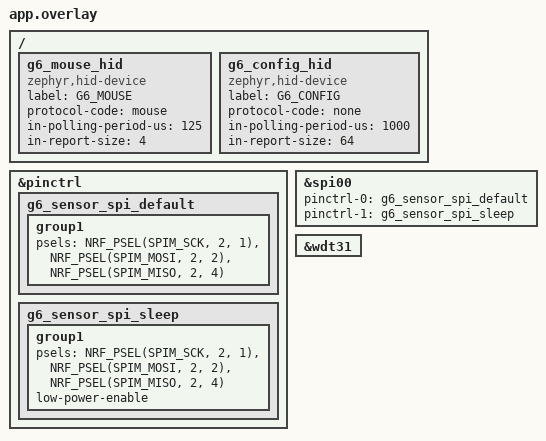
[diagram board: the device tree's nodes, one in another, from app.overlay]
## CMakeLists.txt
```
cmake_minimum_required(VERSION 3.20.0)

find_package(Zephyr REQUIRED HINTS $ENV{ZEPHYR_BASE})
project(g6_he_replacement)

target_include_directories(app PRIVATE include)

target_sources(app PRIVATE
  src/g6_config.c
  src/g6_input_guard.c
  src/g6_hw_nrf54.c
  src/g6_usb.c
  src/main.c
)
```

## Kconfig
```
mainmenu "G6 HE replacement firmware"

source "Kconfig.zephyr"
```

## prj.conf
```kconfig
CONFIG_USB_DEVICE_STACK_NEXT=y
CONFIG_USBD_HID_SUPPORT=y
CONFIG_USBD_HID_SET_POLLING_PERIOD=y
CONFIG_HWINFO=y

CONFIG_GPIO=y
CONFIG_SPI=y
CONFIG_WATCHDOG=y

CONFIG_LOG=n
CONFIG_CONSOLE=n
CONFIG_SERIAL=n
CONFIG_UART_CONSOLE=n

CONFIG_MAIN_STACK_SIZE=4096
CONFIG_SYSTEM_WORKQUEUE_STACK_SIZE=2048
CONFIG_ASSERT=y

CONFIG_BUILD_OUTPUT_BIN=y
CONFIG_BUILD_OUTPUT_HEX=y
```

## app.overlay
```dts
#include <zephyr/dt-bindings/gpio/gpio.h>
#include <zephyr/dt-bindings/pinctrl/nrf-pinctrl.h>

&pinctrl {
	g6_sensor_spi_default: g6_sensor_spi_default {
		group1 {
			psels = <NRF_PSEL(SPIM_SCK, 2, 1)>,
				<NRF_PSEL(SPIM_MOSI, 2, 2)>,
				<NRF_PSEL(SPIM_MISO, 2, 4)>;
		};
	};

	g6_sensor_spi_sleep: g6_sensor_spi_sleep {
		group1 {
			psels = <NRF_PSEL(SPIM_SCK, 2, 1)>,
				<NRF_PSEL(SPIM_MOSI, 2, 2)>,
				<NRF_PSEL(SPIM_MISO, 2, 4)>;
			low-power-enable;
		};
	};
};

&spi00 {
	status = "okay";
	pinctrl-0 = <&g6_sensor_spi_default>;
	pinctrl-1 = <&g6_sensor_spi_sleep>;
	pinctrl-names = "default", "sleep";
};

/ {
	g6_mouse_hid: g6_mouse_hid {
		compatible = "zephyr,hid-device";
		label = "G6_MOUSE";
		protocol-code = "mouse";
		in-polling-period-us = <125>;
		in-report-size = <4>;
	};

	g6_config_hid: g6_config_hid {
		compatible = "zephyr,hid-device";
		label = "G6_CONFIG";
		protocol-code = "none";
		in-polling-period-us = <1000>;
		in-report-size = <64>;
	};
};

&wdt31 {
	status = "okay";
};
```

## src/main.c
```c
#include <errno.h>
#include <string.h>

#include <zephyr/device.h>
#include <zephyr/drivers/watchdog.h>
#include <zephyr/kernel.h>
#include <zephyr/sys/atomic.h>
#include <zephyr/sys/util.h>
#include <zephyr/usb/class/hid.h>
#include <zephyr/usb/class/usbd_hid.h>
#include <zephyr/usb/usbd.h>

#include "g6_config.h"
#include "g6_hw.h"
#include "g6_input_guard.h"
#include "g6_usb.h"

#define G6_MOUSE_REPORT_SIZE 4U
#define G6_INPUT_LOOP_US 50U
#define G6_WATCHDOG_TIMEOUT_MS 1500U
#define G6_USB_RESTART_DELAY_MS 250U

static const uint8_t mouse_report_desc[] = HID_MOUSE_REPORT_DESC(8);

static const uint8_t config_report_desc[] = {
	HID_USAGE_PAGE16(0xFF00),
	HID_USAGE(0x01),
	HID_COLLECTION(HID_COLLECTION_APPLICATION),
		HID_REPORT_ID(G6_FEATURE_REPORT_ID),
		HID_LOGICAL_MIN8(0),
		HID_LOGICAL_MAX16(0xFF, 0x00),
		HID_REPORT_SIZE(8),
		HID_REPORT_COUNT(G6_FEATURE_FRAME_SIZE),
		HID_FEATURE(0x02),
	HID_END_COLLECTION,
};

static const struct device *const mouse_dev =
	DEVICE_DT_GET(DT_NODELABEL(g6_mouse_hid));
static const struct device *const config_dev =
	DEVICE_DT_GET(DT_NODELABEL(g6_config_hid));
static const struct device *const watchdog_dev =
	DEVICE_DT_GET(DT_ALIAS(watchdog0));

static struct g6_config active_config;
static struct g6_health health;
static struct g6_input_guard input_guard;
static uint8_t feature_response[G6_FEATURE_FRAME_SIZE];
static struct k_mutex state_lock;
static atomic_t mouse_ready;
static atomic_t config_ready;
static int watchdog_channel = -1;
static struct usbd_context *usb_context;
static struct k_work_delayable usb_restart_work;
static uint32_t pending_polling_period_us;

static void record_error(int ret)
{
	if (ret >= 0) {
		return;
	}
	k_mutex_lock(&state_lock, K_FOREVER);
	health.last_error = (uint32_t)-ret;
	k_mutex_unlock(&state_lock);
}

static void usb_restart_handler(struct k_work *work)
{
	uint32_t period_us = pending_polling_period_us;
	int ret;

	ARG_UNUSED(work);
	atomic_clear(&mouse_ready);
	atomic_clear(&config_ready);

	ret = usbd_disable(usb_context);
	if (ret != 0) {
		record_error(ret);
		return;
	}
	ret = usbd_shutdown(usb_context);
	if (ret != 0) {
		record_error(ret);
		return;
	}
	ret = hid_device_set_in_polling(mouse_dev, period_us);
	if (ret != 0) {
		record_error(ret);
		return;
	}
	ret = usbd_init(usb_context);
	if (ret != 0) {
		record_error(ret);
		return;
	}
	ret = usbd_enable(usb_context);
	record_error(ret);
}

static void update_health_locked(void)
{
	health.uptime_ms = k_uptime_get_32();
	health.sensor_ready = g6_hw_sensor_ready();
	health.buttons_ready = g6_hw_buttons_ready();
	health.usb_ready = atomic_get(&mouse_ready) &&
			   atomic_get(&config_ready);
	health.recovery_available = 0U;
}

static void apply_active_config_locked(uint16_t old_polling)
{
	int ret = g6_hw_apply_config(&active_config);

	if (ret != 0) {
		health.last_error = (uint32_t)-ret;
	}
	if (active_config.polling_hz != old_polling) {
		pending_polling_period_us =
			g6_polling_period_us(active_config.polling_hz);
		k_work_reschedule(&usb_restart_work,
				  K_MSEC(G6_USB_RESTART_DELAY_MS));
	}
}

static void process_control_event_locked(enum g6_control_event event)
{
	uint16_t old_polling = active_config.polling_hz;

	if (event == G6_CONTROL_CYCLE_POLLING) {
		g6_cycle_polling(&active_config);
	} else if (event == G6_CONTROL_CYCLE_DPI) {
		g6_cycle_dpi(&active_config);
	} else {
		return;
	}

	/* A mode/config shortcut must not leave a host-side pressed button. */
	g6_input_guard_reset(&input_guard);
	health.control_events++;
	apply_active_config_locked(old_polling);
}

static void iface_ready(const struct device *dev, bool ready)
{
	if (dev == mouse_dev) {
		atomic_set(&mouse_ready, ready);
	} else if (dev == config_dev) {
		atomic_set(&config_ready, ready);
	}
}

static int config_get_report(const struct device *dev, uint8_t type,
			     uint8_t id, uint16_t len, uint8_t *buf)
{
	uint16_t copy_len;

	ARG_UNUSED(dev);
	if (type != HID_REPORT_TYPE_FEATURE ||
	    id != G6_FEATURE_REPORT_ID || buf == NULL) {
		return -ENOTSUP;
	}

	copy_len = MIN(len, (uint16_t)G6_FEATURE_FRAME_SIZE);
	k_mutex_lock(&state_lock, K_FOREVER);
	memcpy(buf, feature_response, copy_len);
	k_mutex_unlock(&state_lock);
	return copy_len;
}

static int config_set_report(const struct device *dev, uint8_t type,
			     uint8_t id, uint16_t len, const uint8_t *buf)
{
	const uint8_t *frame = buf;
	enum g6_status status;
	uint16_t old_polling;

	ARG_UNUSED(dev);
	if (type != HID_REPORT_TYPE_FEATURE ||
	    id != G6_FEATURE_REPORT_ID || buf == NULL) {
		return -ENOTSUP;
	}

	if (len == G6_FEATURE_FRAME_SIZE + 1U &&
	    buf[0] == G6_FEATURE_REPORT_ID) {
		frame = &buf[1];
		len--;
	}
	if (len != G6_FEATURE_FRAME_SIZE) {
		return -EMSGSIZE;
	}

	k_mutex_lock(&state_lock, K_FOREVER);
	old_polling = active_config.polling_hz;
	update_health_locked();
	status = g6_process_command(&active_config, &health, frame,
				    feature_response);
	if (status == G6_STATUS_OK) {
		g6_input_guard_reset(&input_guard);
		apply_active_config_locked(old_polling);
	}
	k_mutex_unlock(&state_lock);
	return 0;
}

static struct hid_device_ops mouse_ops = {
	.iface_ready = iface_ready,
};

static struct hid_device_ops config_ops = {
	.iface_ready = iface_ready,
	.get_report = config_get_report,
	.set_report = config_set_report,
};

static int watchdog_start(void)
{
	struct wdt_timeout_cfg timeout = {
		.window = {
			.min = 0U,
			.max = G6_WATCHDOG_TIMEOUT_MS,
		},
		.callback = NULL,
		.flags = WDT_FLAG_RESET_SOC,
	};
	int ret;

	if (!device_is_ready(watchdog_dev)) {
		return -ENODEV;
	}
	watchdog_channel = wdt_install_timeout(watchdog_dev, &timeout);
	if (watchdog_channel < 0) {
		return watchdog_channel;
	}
	ret = wdt_setup(watchdog_dev, WDT_OPT_PAUSE_HALTED_BY_DBG);
	return ret;
}

static void watchdog_feed_if_healthy(void)
{
	int ret;

	if (watchdog_channel < 0) {
		return;
	}
	ret = wdt_feed(watchdog_dev, watchdog_channel);
	k_mutex_lock(&state_lock, K_FOREVER);
	if (ret == 0) {
		health.watchdog_feeds++;
	} else {
		health.last_error = (uint32_t)-ret;
	}
	k_mutex_unlock(&state_lock);
}

static int initialize(void)
{
	struct usbd_context *usb;
	int ret;

	k_mutex_init(&state_lock);
	k_work_init_delayable(&usb_restart_work, usb_restart_handler);
	g6_config_defaults(&active_config);
	g6_input_guard_reset(&input_guard);
	g6_frame_init(feature_response, 0U, G6_CMD_GET_CONFIG);
	feature_response[7] = G6_STATUS_NOT_READY;
	g6_frame_finalize(feature_response);

	ret = g6_hw_init();
	if (ret != 0) {
		return ret;
	}

	if (!device_is_ready(mouse_dev) || !device_is_ready(config_dev)) {
		return -ENODEV;
	}
	ret = hid_device_register(mouse_dev, mouse_report_desc,
				  sizeof(mouse_report_desc), &mouse_ops);
	if (ret != 0) {
		return ret;
	}
	ret = hid_device_register(config_dev, config_report_desc,
				  sizeof(config_report_desc), &config_ops);
	if (ret != 0) {
		return ret;
	}
	ret = hid_device_set_in_polling(
		mouse_dev, g6_polling_period_us(active_config.polling_hz));
	if (ret != 0) {
		return ret;
	}

	usb = g6_usb_init();
	if (usb == NULL) {
		return -ENODEV;
	}
	usb_context = usb;
	ret = usbd_enable(usb);
	if (ret != 0) {
		return ret;
	}

	ret = watchdog_start();
	return ret == -ENODEV ? 0 : ret;
}

int main(void)
{
	uint8_t report[G6_MOUSE_REPORT_SIZE] __aligned(4);
	uint32_t last_watchdog_feed = 0U;
	int ret = initialize();

	if (ret != 0) {
		k_panic();
	}

	while (true) {
		struct g6_input_sample sample;
		enum g6_control_event control_event = G6_CONTROL_NONE;
		uint8_t filtered_buttons = 0U;
		bool guard_changed = false;
		uint32_t now;

		ret = g6_hw_poll(&sample);
		k_mutex_lock(&state_lock, K_FOREVER);
		health.input_loops++;
		if (ret != 0) {
			health.last_error = (uint32_t)-ret;
		}
		k_mutex_unlock(&state_lock);

		now = k_uptime_get_32();
		if (ret == 0) {
			guard_changed = g6_input_guard_process(
				&input_guard, now, sample.raw_buttons,
				&filtered_buttons, &control_event);
			if (control_event != G6_CONTROL_NONE) {
				k_mutex_lock(&state_lock, K_FOREVER);
				process_control_event_locked(control_event);
				health.suppressed_chord_reports++;
				k_mutex_unlock(&state_lock);
			}
		}

		if (ret == 0 && (sample.changed || guard_changed) &&
		    atomic_get(&mouse_ready)) {
			k_mutex_lock(&state_lock, K_FOREVER);
			report[0] = g6_apply_button_map(
				&active_config, filtered_buttons);
			k_mutex_unlock(&state_lock);
			report[1] = (uint8_t)CLAMP(sample.dx, -127, 127);
			report[2] = (uint8_t)CLAMP(sample.dy, -127, 127);
			report[3] = (uint8_t)sample.wheel;

			ret = hid_device_submit_report(
				mouse_dev, sizeof(report), report);
			k_mutex_lock(&state_lock, K_FOREVER);
			if (ret == 0) {
				health.usb_reports++;
			} else {
				health.usb_errors++;
				health.last_error = (uint32_t)-ret;
			}
			k_mutex_unlock(&state_lock);
		}

		if ((now - last_watchdog_feed) >=
		    (G6_WATCHDOG_TIMEOUT_MS / 3U)) {
			watchdog_feed_if_healthy();
			last_watchdog_feed = now;
		}

		k_busy_wait(G6_INPUT_LOOP_US);
	}
}
```

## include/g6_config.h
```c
#ifndef G6_CONFIG_H
#define G6_CONFIG_H

#include <stdbool.h>
#include <stddef.h>
#include <stdint.h>

#define G6_PROTOCOL_VERSION 1U
#define G6_FIRMWARE_VERSION "0.2.0-dvt1"
#define G6_FEATURE_REPORT_ID 0x51U
#define G6_FEATURE_FRAME_SIZE 63U
#define G6_FEATURE_PAYLOAD_SIZE 50U

#define G6_DPI_MIN 1U
#define G6_DPI_MAX 40000U
#define G6_SENSOR_FPS_MIN 20000U
#define G6_SENSOR_FPS_MAX 20000U
#define G6_BUTTON_COUNT 8U

enum g6_command {
	G6_CMD_GET_CAPABILITIES = 0x01,
	G6_CMD_GET_CONFIG = 0x02,
	G6_CMD_SET_DPI = 0x10,
	G6_CMD_SET_POLLING = 0x11,
	G6_CMD_SET_SENSOR_FPS = 0x12,
	G6_CMD_SET_BUTTON_MAP = 0x13,
	G6_CMD_SET_SWITCH_MODE = 0x14,
	G6_CMD_SAVE = 0x20,
	G6_CMD_FACTORY_RESET = 0x21,
	G6_CMD_GET_HEALTH = 0x30,
	G6_CMD_REBOOT_RECOVERY = 0x31,
};

enum g6_status {
	G6_STATUS_OK = 0,
	G6_STATUS_BAD_MAGIC = 1,
	G6_STATUS_BAD_VERSION = 2,
	G6_STATUS_BAD_LENGTH = 3,
	G6_STATUS_BAD_CRC = 4,
	G6_STATUS_BAD_COMMAND = 5,
	G6_STATUS_BAD_VALUE = 6,
	G6_STATUS_NOT_READY = 7,
	G6_STATUS_NOT_IMPLEMENTED = 8,
};

enum g6_switch_mode {
	G6_SWITCH_OPTICAL = 0,
	G6_SWITCH_MAGNETIC = 1,
	G6_SWITCH_HYBRID = 2,
};

enum g6_button_action {
	G6_ACTION_NONE = 0,
	G6_ACTION_LEFT = 1,
	G6_ACTION_RIGHT = 2,
	G6_ACTION_MIDDLE = 3,
	G6_ACTION_BACK = 4,
	G6_ACTION_FORWARD = 5,
	G6_ACTION_DPI_UP = 6,
	G6_ACTION_DPI_DOWN = 7,
};

struct g6_config {
	uint16_t dpi;
	uint16_t polling_hz;
	uint16_t sensor_fps;
	uint8_t switch_mode;
	uint8_t button_map[G6_BUTTON_COUNT];
};

struct g6_health {
	uint32_t uptime_ms;
	uint32_t input_loops;
	uint32_t usb_reports;
	uint32_t usb_errors;
	uint32_t watchdog_feeds;
	uint32_t last_error;
	uint8_t sensor_ready;
	uint8_t buttons_ready;
	uint8_t usb_ready;
	uint8_t recovery_available;
	uint32_t control_events;
	uint32_t suppressed_chord_reports;
};

void g6_config_defaults(struct g6_config *cfg);
bool g6_config_valid(const struct g6_config *cfg);
bool g6_polling_hz_valid(uint16_t polling_hz);
uint32_t g6_polling_period_us(uint16_t polling_hz);
void g6_cycle_dpi(struct g6_config *cfg);
void g6_cycle_polling(struct g6_config *cfg);
uint8_t g6_apply_button_map(const struct g6_config *cfg, uint8_t raw_buttons);

uint32_t g6_crc32(const uint8_t *data, size_t len);
void g6_frame_init(uint8_t frame[G6_FEATURE_FRAME_SIZE],
		   uint8_t sequence, uint8_t command);
void g6_frame_finalize(uint8_t frame[G6_FEATURE_FRAME_SIZE]);
enum g6_status g6_frame_validate(
	const uint8_t frame[G6_FEATURE_FRAME_SIZE]);

enum g6_status g6_process_command(
	struct g6_config *cfg,
	const struct g6_health *health,
	const uint8_t request[G6_FEATURE_FRAME_SIZE],
	uint8_t response[G6_FEATURE_FRAME_SIZE]);

#endif
```

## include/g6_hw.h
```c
#ifndef G6_HW_H
#define G6_HW_H

#include <stdbool.h>
#include <stdint.h>

#include "g6_config.h"

struct g6_input_sample {
	int16_t dx;
	int16_t dy;
	int8_t wheel;
	uint8_t raw_buttons;
	bool changed;
};

int g6_hw_init(void);
int g6_hw_apply_config(const struct g6_config *cfg);
int g6_hw_poll(struct g6_input_sample *sample);
bool g6_hw_sensor_ready(void);
bool g6_hw_buttons_ready(void);

#endif
```

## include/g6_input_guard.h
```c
#ifndef G6_INPUT_GUARD_H
#define G6_INPUT_GUARD_H

#include <stdbool.h>
#include <stdint.h>

/* Raw board button bit positions: left, right, middle, back, forward. */
#define G6_RAW_BUTTON_MIDDLE (1U << 2)
#define G6_RAW_BUTTON_BACK (1U << 3)
#define G6_RAW_BUTTON_FORWARD (1U << 4)

enum g6_control_event {
	G6_CONTROL_NONE = 0,
	G6_CONTROL_CYCLE_POLLING,
	G6_CONTROL_CYCLE_DPI,
};

/*
 * The production DVT reports ghost side-button input while the physical
 * middle+side shortcuts are used. This guard delays publication of chord
 * members briefly, consumes a recognised shortcut, and always emits a
 * neutral release when a consumed chord ends.
 */
struct g6_input_guard {
	uint8_t reported_buttons;
	uint32_t chord_deadline_ms;
	bool chord_window_active;
	bool combo_active;
};

void g6_input_guard_reset(struct g6_input_guard *guard);
bool g6_input_guard_process(struct g6_input_guard *guard, uint32_t now_ms,
			    uint8_t raw_buttons, uint8_t *filtered_buttons,
			    enum g6_control_event *event);

#endif
```

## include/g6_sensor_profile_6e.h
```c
#ifndef G6_SENSOR_PROFILE_6E_H
#define G6_SENSOR_PROFILE_6E_H

#include <stdint.h>

/* 268 register/value pairs from production image address 0x2004f725. */
static const uint8_t g6_sensor_6e_init_pairs[] = {
	0x7f, 0x07, 0x40, 0x41, 0x41, 0x0f, 0x42, 0x28,
	0x43, 0x00, 0x4a, 0x08, 0x51, 0x16, 0x53, 0x04,
	0x7f, 0x0e, 0x55, 0xfc, 0x56, 0xff, 0x7f, 0x01,
	0x43, 0xf8, 0x55, 0x28, 0x57, 0x1a, 0x5a, 0x20,
	0x5b, 0x0c, 0x7f, 0x05, 0x43, 0x64, 0x44, 0x04,
	0x46, 0x1b, 0x49, 0xff, 0x55, 0xfc, 0x5e, 0xc3,
	0x5f, 0x80, 0x61, 0x31, 0x6d, 0xea, 0x6e, 0xcf,
	0x4a, 0x15, 0x60, 0x13, 0x7b, 0x48, 0x7f, 0x06,
	0x70, 0x14, 0x71, 0xe0, 0x6b, 0x20, 0x6d, 0x78,
	0x6e, 0x60, 0x44, 0x23, 0x46, 0xb9, 0x53, 0x01,
	0x61, 0x00, 0x63, 0x00, 0x7f, 0x08, 0x63, 0x08,
	0x6b, 0x40, 0x6d, 0x68, 0x73, 0x18, 0x75, 0x2c,
	0x79, 0xc8, 0x7a, 0x0d, 0x7c, 0x2a, 0x7f, 0x09,
	0x53, 0x4a, 0x60, 0x1f, 0x61, 0x1f, 0x62, 0x01,
	0x63, 0x01, 0x64, 0x1f, 0x65, 0x1f, 0x66, 0x01,
	0x67, 0x01, 0x68, 0x01, 0x69, 0x01, 0x6a, 0x1f,
	0x6b, 0x1f, 0x6c, 0x01, 0x6d, 0x01, 0x6e, 0x1f,
	0x6f, 0x1f, 0x40, 0x03, 0x41, 0x00, 0x42, 0x04,
	0x43, 0x28, 0x44, 0x88, 0x45, 0x11, 0x47, 0x03,
	0x4f, 0x0c, 0x51, 0x08, 0x73, 0x0a, 0x7f, 0x0a,
	0x44, 0x43, 0x48, 0x80, 0x50, 0x25, 0x51, 0x8f,
	0x52, 0x40, 0x53, 0x1f, 0x56, 0x90, 0x57, 0x01,
	0x4f, 0xd0, 0x59, 0x3f, 0x7f, 0x0c, 0x41, 0x10,
	0x43, 0x38, 0x44, 0x02, 0x45, 0x02, 0x4e, 0x0a,
	0x47, 0x02, 0x48, 0x01, 0x49, 0x04, 0x55, 0x02,
	0x5c, 0x9e, 0x42, 0x00, 0x4a, 0x20, 0x4b, 0x1f,
	0x4c, 0x68, 0x4d, 0x90, 0x53, 0x1e, 0x54, 0x1a,
	0x50, 0x14, 0x51, 0x15, 0x61, 0x18, 0x62, 0x08,
	0x7f, 0x0d, 0x50, 0x66, 0x52, 0x09, 0x51, 0x00,
	0x5a, 0x47, 0x5b, 0x66, 0x5c, 0xf4, 0x5d, 0x6c,
	0x71, 0x28, 0x70, 0x00, 0x73, 0x29, 0x72, 0x00,
	0x75, 0x28, 0x74, 0x00, 0x77, 0x29, 0x76, 0x00,
	0x7f, 0x10, 0x42, 0x1c, 0x43, 0xd0, 0x45, 0x11,
	0x46, 0x20, 0x48, 0x0a, 0x49, 0x0f, 0x4b, 0x09,
	0x4c, 0xc4, 0x7f, 0x14, 0x43, 0x73, 0x52, 0x19,
	0x62, 0x04, 0x63, 0x04, 0x65, 0x81, 0x53, 0x50,
	0x54, 0xd8, 0x7f, 0x15, 0x41, 0xa2, 0x4c, 0x04,
	0x56, 0x28, 0x6f, 0x28, 0x70, 0x04, 0x71, 0x04,
	0x77, 0x02, 0x7d, 0x10, 0x45, 0xf4, 0x47, 0x44,
	0x4b, 0x12, 0x7f, 0x16, 0x57, 0x43, 0x58, 0x43,
	0x59, 0x43, 0x5a, 0x43, 0x5d, 0x32, 0x5e, 0x32,
	0x69, 0x1e, 0x6a, 0x22, 0x6b, 0x22, 0x6c, 0x22,
	0x6d, 0x22, 0x6e, 0x18, 0x6f, 0x18, 0x70, 0x18,
	0x71, 0x18, 0x73, 0x00, 0x74, 0xda, 0x75, 0xbe,
	0x78, 0x0e, 0x7f, 0x18, 0x41, 0x02, 0x43, 0x80,
	0x44, 0x1f, 0x45, 0x01, 0x46, 0x82, 0x48, 0x65,
	0x49, 0x12, 0x4a, 0x0f, 0x4b, 0x00, 0x4c, 0x28,
	0x4d, 0x38, 0x4e, 0x32, 0x4f, 0x71, 0x50, 0x34,
	0x51, 0x54, 0x52, 0x38, 0x53, 0x5f, 0x54, 0x90,
	0x55, 0x7f, 0x59, 0xa6, 0x5a, 0x30, 0x5b, 0x2c,
	0x5c, 0x60, 0x5d, 0x06, 0x5e, 0x01, 0x5f, 0x48,
	0x60, 0x44, 0x61, 0x14, 0x62, 0x2c, 0x63, 0x48,
	0x64, 0x40, 0x65, 0x75, 0x67, 0x4c, 0x69, 0x85,
	0x6b, 0x60, 0x6d, 0xf5, 0x6e, 0x06, 0x6f, 0x06,
	0x70, 0x22, 0x71, 0xf2, 0x72, 0xf6, 0x76, 0x00,
	0x77, 0x32, 0x78, 0x88, 0x79, 0x99, 0x7a, 0x00,
	0x7e, 0xb0, 0x7f, 0x19, 0x40, 0x43, 0x41, 0x32,
	0x44, 0x32, 0x46, 0xe6, 0x4b, 0x01, 0x4c, 0x01,
	0x52, 0x15, 0x53, 0x12, 0x54, 0x23, 0x56, 0x70,
	0x57, 0x22, 0x58, 0x13, 0x5f, 0x7f, 0x6e, 0x8f,
	0x7f, 0x00, 0x5b, 0x40, 0x45, 0x3f, 0x44, 0x1f,
	0x63, 0x3f, 0x62, 0x1f, 0x48, 0xa6, 0x49, 0x13,
	0x4a, 0x83, 0x4b, 0x13, 0x4f, 0xfc, 0x4e, 0x4e,
	0x52, 0x70, 0x51, 0x4e, 0x5a, 0x80, 0x47, 0x01,
	0x57, 0x20, 0x64, 0x08, 0x65, 0x07, 0x66, 0x13,
	0x77, 0x9e, 0x7d, 0x09, 0x7f, 0x07, 0x40, 0x40,
	0x7f, 0x00, 0x40, 0x80, 0x55, 0x02, 0x22, 0x01,
};

/* Four register/value pairs from production image address 0x2004f71d. */
static const uint8_t g6_sensor_6e_post_pairs[] = {
	0x22, 0x00, 0x55, 0x00, 0x40, 0x00, 0x68, 0x01,
};

#endif
```

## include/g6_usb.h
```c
#ifndef G6_USB_H
#define G6_USB_H

#include <zephyr/usb/usbd.h>

struct usbd_context *g6_usb_init(void);

#endif
```

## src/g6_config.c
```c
#include "g6_config.h"

#include <string.h>

#define G6_FRAME_MAGIC_0 'G'
#define G6_FRAME_MAGIC_1 '6'
#define G6_FRAME_MAGIC_2 'H'
#define G6_FRAME_MAGIC_3 '1'

#define G6_FRAME_VERSION_OFFSET 4U
#define G6_FRAME_SEQUENCE_OFFSET 5U
#define G6_FRAME_COMMAND_OFFSET 6U
#define G6_FRAME_STATUS_OFFSET 7U
#define G6_FRAME_LENGTH_OFFSET 8U
#define G6_FRAME_PAYLOAD_OFFSET 9U
#define G6_FRAME_CRC_OFFSET 59U

#define G6_CAP_WIRED_USB (1U << 0)
#define G6_CAP_HIGH_SPEED_USB (1U << 1)
#define G6_CAP_DYNAMIC_POLLING (1U << 2)
#define G6_CAP_BUTTON_REMAP (1U << 3)
#define G6_CAP_WATCHDOG (1U << 4)
#define G6_CAP_SENSOR_PROFILE_6E (1U << 5)
#define G6_CAP_OPTICAL_SWITCHES (1U << 6)

static uint16_t get_le16(const uint8_t *src)
{
	return (uint16_t)src[0] | ((uint16_t)src[1] << 8);
}

static uint32_t get_le32(const uint8_t *src)
{
	return (uint32_t)src[0] |
	       ((uint32_t)src[1] << 8) |
	       ((uint32_t)src[2] << 16) |
	       ((uint32_t)src[3] << 24);
}

static void put_le16(uint8_t *dst, uint16_t value)
{
	dst[0] = (uint8_t)value;
	dst[1] = (uint8_t)(value >> 8);
}

static void put_le32(uint8_t *dst, uint32_t value)
{
	dst[0] = (uint8_t)value;
	dst[1] = (uint8_t)(value >> 8);
	dst[2] = (uint8_t)(value >> 16);
	dst[3] = (uint8_t)(value >> 24);
}

void g6_config_defaults(struct g6_config *cfg)
{
	static const uint8_t default_map[G6_BUTTON_COUNT] = {
		G6_ACTION_LEFT,
		G6_ACTION_RIGHT,
		G6_ACTION_MIDDLE,
		G6_ACTION_BACK,
		G6_ACTION_FORWARD,
		G6_ACTION_DPI_UP,
		G6_ACTION_DPI_DOWN,
		G6_ACTION_NONE,
	};

	cfg->dpi = 1600U;
	cfg->polling_hz = 1000U;
	cfg->sensor_fps = 20000U;
	cfg->switch_mode = G6_SWITCH_OPTICAL;
	memcpy(cfg->button_map, default_map, sizeof(default_map));
}

bool g6_polling_hz_valid(uint16_t polling_hz)
{
	switch (polling_hz) {
	case 125U:
	case 500U:
	case 1000U:
	case 2000U:
	case 4000U:
	case 8000U:
		return true;
	default:
		return false;
	}
}

uint32_t g6_polling_period_us(uint16_t polling_hz)
{
	return g6_polling_hz_valid(polling_hz) ?
		       (1000000U / polling_hz) : 0U;
}

void g6_cycle_dpi(struct g6_config *cfg)
{
	static const uint16_t stages[] = {400U, 800U, 1600U, 3200U, 5000U};
	size_t i;

	if (cfg == NULL) {
		return;
	}
	for (i = 0U; i < sizeof(stages) / sizeof(stages[0]); ++i) {
		if (cfg->dpi == stages[i]) {
			cfg->dpi = stages[(i + 1U) %
					(sizeof(stages) / sizeof(stages[0]))];
			return;
		}
	}
	cfg->dpi = stages[0];
}

void g6_cycle_polling(struct g6_config *cfg)
{
	static const uint16_t stages[] = {125U, 500U, 1000U, 2000U, 4000U, 8000U};
	size_t i;

	if (cfg == NULL) {
		return;
	}
	for (i = 0U; i < sizeof(stages) / sizeof(stages[0]); ++i) {
		if (cfg->polling_hz == stages[i]) {
			cfg->polling_hz = stages[(i + 1U) %
					(sizeof(stages) / sizeof(stages[0]))];
			return;
		}
	}
	cfg->polling_hz = stages[0];
}

bool g6_config_valid(const struct g6_config *cfg)
{
	size_t i;

	if (cfg == NULL ||
	    cfg->dpi < G6_DPI_MIN || cfg->dpi > G6_DPI_MAX ||
	    !g6_polling_hz_valid(cfg->polling_hz) ||
	    cfg->sensor_fps < G6_SENSOR_FPS_MIN ||
	    cfg->sensor_fps > G6_SENSOR_FPS_MAX ||
	    cfg->switch_mode > G6_SWITCH_HYBRID) {
		return false;
	}

	for (i = 0U; i < G6_BUTTON_COUNT; ++i) {
		if (cfg->button_map[i] > G6_ACTION_DPI_DOWN) {
			return false;
		}
	}

	return true;
}

uint8_t g6_apply_button_map(const struct g6_config *cfg, uint8_t raw_buttons)
{
	uint8_t mapped = 0U;
	size_t i;

	for (i = 0U; i < G6_BUTTON_COUNT; ++i) {
		uint8_t action;

		if ((raw_buttons & (1U << i)) == 0U) {
			continue;
		}

		action = cfg->button_map[i];
		if (action >= G6_ACTION_LEFT && action <= G6_ACTION_FORWARD) {
			mapped |= 1U << (action - G6_ACTION_LEFT);
		}
	}

	return mapped;
}

uint32_t g6_crc32(const uint8_t *data, size_t len)
{
	uint32_t crc = 0xFFFFFFFFU;
	size_t i;

	for (i = 0U; i < len; ++i) {
		uint32_t byte = data[i];
		unsigned int bit;

		crc ^= byte;
		for (bit = 0U; bit < 8U; ++bit) {
			uint32_t mask = 0U - (crc & 1U);
			crc = (crc >> 1) ^ (0xEDB88320U & mask);
		}
	}

	return ~crc;
}

void g6_frame_init(uint8_t frame[G6_FEATURE_FRAME_SIZE],
		   uint8_t sequence, uint8_t command)
{
	memset(frame, 0, G6_FEATURE_FRAME_SIZE);
	frame[0] = G6_FRAME_MAGIC_0;
	frame[1] = G6_FRAME_MAGIC_1;
	frame[2] = G6_FRAME_MAGIC_2;
	frame[3] = G6_FRAME_MAGIC_3;
	frame[G6_FRAME_VERSION_OFFSET] = G6_PROTOCOL_VERSION;
	frame[G6_FRAME_SEQUENCE_OFFSET] = sequence;
	frame[G6_FRAME_COMMAND_OFFSET] = command;
}

void g6_frame_finalize(uint8_t frame[G6_FEATURE_FRAME_SIZE])
{
	put_le32(&frame[G6_FRAME_CRC_OFFSET],
		 g6_crc32(frame, G6_FRAME_CRC_OFFSET));
}

enum g6_status g6_frame_validate(
	const uint8_t frame[G6_FEATURE_FRAME_SIZE])
{
	uint32_t expected;
	uint32_t actual;

	if (frame[0] != G6_FRAME_MAGIC_0 ||
	    frame[1] != G6_FRAME_MAGIC_1 ||
	    frame[2] != G6_FRAME_MAGIC_2 ||
	    frame[3] != G6_FRAME_MAGIC_3) {
		return G6_STATUS_BAD_MAGIC;
	}
	if (frame[G6_FRAME_VERSION_OFFSET] != G6_PROTOCOL_VERSION) {
		return G6_STATUS_BAD_VERSION;
	}
	if (frame[G6_FRAME_LENGTH_OFFSET] > G6_FEATURE_PAYLOAD_SIZE) {
		return G6_STATUS_BAD_LENGTH;
	}

	expected = get_le32(&frame[G6_FRAME_CRC_OFFSET]);
	actual = g6_crc32(frame, G6_FRAME_CRC_OFFSET);
	return expected == actual ? G6_STATUS_OK : G6_STATUS_BAD_CRC;
}

static void response_status(
	uint8_t response[G6_FEATURE_FRAME_SIZE], enum g6_status status)
{
	response[G6_FRAME_STATUS_OFFSET] = (uint8_t)status;
	g6_frame_finalize(response);
}

static void response_config(const struct g6_config *cfg, uint8_t *payload)
{
	put_le16(&payload[0], cfg->dpi);
	put_le16(&payload[2], cfg->polling_hz);
	put_le16(&payload[4], cfg->sensor_fps);
	payload[6] = cfg->switch_mode;
	memcpy(&payload[7], cfg->button_map, G6_BUTTON_COUNT);
}

enum g6_status g6_process_command(
	struct g6_config *cfg,
	const struct g6_health *health,
	const uint8_t request[G6_FEATURE_FRAME_SIZE],
	uint8_t response[G6_FEATURE_FRAME_SIZE])
{
	enum g6_status status = g6_frame_validate(request);
	const uint8_t *payload = &request[G6_FRAME_PAYLOAD_OFFSET];
	uint8_t *out = &response[G6_FRAME_PAYLOAD_OFFSET];
	uint8_t command = request[G6_FRAME_COMMAND_OFFSET];

	g6_frame_init(response, request[G6_FRAME_SEQUENCE_OFFSET], command);
	if (status != G6_STATUS_OK) {
		response_status(response, status);
		return status;
	}

	switch (command) {
	case G6_CMD_GET_CAPABILITIES:
		put_le16(&out[0], G6_DPI_MIN);
		put_le16(&out[2], G6_DPI_MAX);
		put_le16(&out[4], G6_SENSOR_FPS_MIN);
		put_le16(&out[6], G6_SENSOR_FPS_MAX);
		put_le16(&out[8], 0x003FU);
		out[10] = G6_BUTTON_COUNT;
		out[11] = 1U;
		put_le32(&out[12],
			 G6_CAP_WIRED_USB |
			 G6_CAP_HIGH_SPEED_USB |
			 G6_CAP_DYNAMIC_POLLING |
			 G6_CAP_BUTTON_REMAP |
			 G6_CAP_WATCHDOG |
			 G6_CAP_SENSOR_PROFILE_6E |
			 G6_CAP_OPTICAL_SWITCHES);
		response[G6_FRAME_LENGTH_OFFSET] = 16U;
		break;
	case G6_CMD_GET_CONFIG:
		response_config(cfg, out);
		response[G6_FRAME_LENGTH_OFFSET] = 15U;
		break;
	case G6_CMD_SET_DPI:
		if (request[G6_FRAME_LENGTH_OFFSET] != 2U) {
			status = G6_STATUS_BAD_LENGTH;
		} else {
			uint16_t dpi = get_le16(payload);
			if (dpi < G6_DPI_MIN || dpi > G6_DPI_MAX) {
				status = G6_STATUS_BAD_VALUE;
			} else {
				cfg->dpi = dpi;
			}
		}
		break;
	case G6_CMD_SET_POLLING:
		if (request[G6_FRAME_LENGTH_OFFSET] != 2U) {
			status = G6_STATUS_BAD_LENGTH;
		} else {
			uint16_t polling_hz = get_le16(payload);
			if (!g6_polling_hz_valid(polling_hz)) {
				status = G6_STATUS_BAD_VALUE;
			} else {
				cfg->polling_hz = polling_hz;
			}
		}
		break;
	case G6_CMD_SET_SENSOR_FPS:
		if (request[G6_FRAME_LENGTH_OFFSET] != 2U) {
			status = G6_STATUS_BAD_LENGTH;
		} else {
			uint16_t fps = get_le16(payload);
			if (fps < G6_SENSOR_FPS_MIN || fps > G6_SENSOR_FPS_MAX) {
				status = G6_STATUS_BAD_VALUE;
			} else {
				cfg->sensor_fps = fps;
			}
		}
		break;
	case G6_CMD_SET_BUTTON_MAP:
		if (request[G6_FRAME_LENGTH_OFFSET] != G6_BUTTON_COUNT) {
			status = G6_STATUS_BAD_LENGTH;
		} else {
			size_t i;
			for (i = 0U; i < G6_BUTTON_COUNT; ++i) {
				if (payload[i] > G6_ACTION_DPI_DOWN) {
					status = G6_STATUS_BAD_VALUE;
					break;
				}
			}
			if (status == G6_STATUS_OK) {
				memcpy(cfg->button_map, payload, G6_BUTTON_COUNT);
			}
		}
		break;
	case G6_CMD_SET_SWITCH_MODE:
		if (request[G6_FRAME_LENGTH_OFFSET] != 1U) {
			status = G6_STATUS_BAD_LENGTH;
		} else if (payload[0] != G6_SWITCH_OPTICAL) {
			status = G6_STATUS_BAD_VALUE;
		} else {
			cfg->switch_mode = payload[0];
		}
		break;
	case G6_CMD_GET_HEALTH:
		if (health == NULL) {
			status = G6_STATUS_NOT_READY;
			break;
		}
		put_le32(&out[0], health->uptime_ms);
		put_le32(&out[4], health->input_loops);
		put_le32(&out[8], health->usb_reports);
		put_le32(&out[12], health->usb_errors);
		put_le32(&out[16], health->watchdog_feeds);
		put_le32(&out[20], health->last_error);
		out[24] = health->sensor_ready;
		out[25] = health->buttons_ready;
		out[26] = health->usb_ready;
		out[27] = health->recovery_available;
		put_le32(&out[28], health->control_events);
		put_le32(&out[32], health->suppressed_chord_reports);
		response[G6_FRAME_LENGTH_OFFSET] = 36U;
		break;
	case G6_CMD_FACTORY_RESET:
		g6_config_defaults(cfg);
		break;
	case G6_CMD_SAVE:
	case G6_CMD_REBOOT_RECOVERY:
		status = G6_STATUS_NOT_IMPLEMENTED;
		break;
	default:
		status = G6_STATUS_BAD_COMMAND;
		break;
	}

	if (status == G6_STATUS_OK &&
	    command >= G6_CMD_SET_DPI &&
	    command <= G6_CMD_SET_SWITCH_MODE) {
		response_config(cfg, out);
		response[G6_FRAME_LENGTH_OFFSET] = 15U;
	}

	response_status(response, status);
	return status;
}
```

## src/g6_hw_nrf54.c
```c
#include "g6_hw.h"
#include "g6_sensor_profile_6e.h"

#include <errno.h>
#include <string.h>

#include <zephyr/device.h>
#include <zephyr/drivers/gpio.h>
#include <zephyr/drivers/spi.h>
#include <zephyr/kernel.h>
#include <zephyr/sys/byteorder.h>
#include <zephyr/sys/util.h>

#define SENSOR_ID_REG 0x00U
#define SENSOR_MOTION_REG 0x16U
#define SENSOR_BOOT_STATUS_REG 0x6cU
#define SENSOR_ID_PROFILE_6E 0x6eU
#define SENSOR_SPI_HZ 16000000U
#define SENSOR_SPI_GUARD_US 1U
#define SENSOR_BOOT_RETRIES 45U

BUILD_ASSERT(sizeof(g6_sensor_6e_init_pairs) == 536U);
BUILD_ASSERT(sizeof(g6_sensor_6e_post_pairs) == 8U);

static const struct device *const gpio0 = DEVICE_DT_GET(DT_NODELABEL(gpio0));
static const struct device *const gpio1 = DEVICE_DT_GET(DT_NODELABEL(gpio1));
static const struct device *const gpio2 = DEVICE_DT_GET(DT_NODELABEL(gpio2));
static const struct device *const sensor_spi =
	DEVICE_DT_GET(DT_NODELABEL(spi00));

static const uint8_t button_pins[] = {9U, 17U, 28U, 30U, 29U};
static const int8_t wheel_transition[16] = {
	0, -1, 1, 0,
	1, 0, 0, -1,
	-1, 0, 0, 1,
	0, 1, -1, 0,
};

static const struct spi_config sensor_spi_config = {
	.frequency = SENSOR_SPI_HZ,
	.operation = SPI_OP_MODE_MASTER | SPI_TRANSFER_MSB |
		     SPI_WORD_SET(8) | SPI_MODE_CPOL | SPI_MODE_CPHA,
	.slave = 0U,
};

static bool sensor_ok;
static bool buttons_ok;
static uint8_t sensor_id;
static uint8_t last_buttons;
static uint8_t last_wheel_state;
static int8_t wheel_accumulator;
static uint32_t spi_failures;
static uint32_t next_sensor_recovery_ms;
static uint16_t active_dpi = 1600U;

static int sensor_set_dpi(uint16_t dpi);

static int sensor_select(bool selected)
{
	return gpio_pin_set_raw(gpio2, 5U, selected ? 0 : 1);
}

static int sensor_transfer(const uint8_t *tx_data, uint8_t *rx_data,
			   size_t length)
{
	struct spi_buf tx_buffer = {
		.buf = (void *)tx_data,
		.len = length,
	};
	struct spi_buf rx_buffer = {
		.buf = rx_data,
		.len = length,
	};
	const struct spi_buf_set tx = {
		.buffers = &tx_buffer,
		.count = 1U,
	};
	const struct spi_buf_set rx = {
		.buffers = &rx_buffer,
		.count = 1U,
	};
	int ret;

	ret = sensor_select(true);
	if (ret != 0) {
		return ret;
	}
	k_busy_wait(SENSOR_SPI_GUARD_US);
	ret = spi_transceive(sensor_spi, &sensor_spi_config, &tx, &rx);
	k_busy_wait(SENSOR_SPI_GUARD_US);
	if (sensor_select(false) != 0 && ret == 0) {
		ret = -EIO;
	}
	if (ret != 0) {
		spi_failures++;
	}
	return ret;
}

static int sensor_write(uint8_t reg, uint8_t value)
{
	uint8_t tx[2] = {(uint8_t)(reg | BIT(7)), value};
	uint8_t rx[2];

	return sensor_transfer(tx, rx, sizeof(tx));
}

static int sensor_read(uint8_t reg, uint8_t *data, size_t length)
{
	uint8_t tx[8] = {0};
	uint8_t rx[8] = {0};
	int ret;

	if (data == NULL || length == 0U || length > 7U) {
		return -EINVAL;
	}
	tx[0] = reg & 0x7fU;
	ret = sensor_transfer(tx, rx, length + 1U);
	if (ret == 0) {
		memcpy(data, &rx[1], length);
	}
	return ret;
}

static int sensor_write_pairs(const uint8_t *pairs, size_t size)
{
	int ret;

	if (pairs == NULL || (size & 1U) != 0U) {
		return -EINVAL;
	}
	for (size_t i = 0; i < size; i += 2U) {
		ret = sensor_write(pairs[i], pairs[i + 1U]);
		if (ret != 0) {
			return ret;
		}
	}
	return 0;
}

static int sensor_reset(void)
{
	int ret;

	k_msleep(50);
	ret = gpio_pin_set_raw(gpio2, 3U, 1);
	if (ret != 0) {
		return ret;
	}
	k_msleep(1);
	ret = gpio_pin_set_raw(gpio2, 3U, 0);
	if (ret != 0) {
		return ret;
	}
	k_busy_wait(100);
	ret = gpio_pin_set_raw(gpio2, 3U, 1);
	if (ret != 0) {
		return ret;
	}
	k_msleep(10);
	return 0;
}

static int sensor_initialize_6e(void)
{
	uint8_t boot_status = 0U;
	int ret;

	ret = sensor_write_pairs(g6_sensor_6e_init_pairs,
				 sizeof(g6_sensor_6e_init_pairs));
	if (ret != 0) {
		return ret;
	}
	k_msleep(1);

	for (uint32_t attempt = 0; attempt < SENSOR_BOOT_RETRIES; attempt++) {
		ret = sensor_read(SENSOR_BOOT_STATUS_REG, &boot_status, 1U);
		if (ret == 0 && boot_status == 0x80U) {
			break;
		}
		k_busy_wait(930);
	}
	if (boot_status != 0x80U) {
		return ret != 0 ? ret : -ETIMEDOUT;
	}

	k_msleep(5);
	return sensor_write_pairs(g6_sensor_6e_post_pairs,
				  sizeof(g6_sensor_6e_post_pairs));
}

static int sensor_try_start(void)
{
	int ret;

	ret = sensor_reset();
	if (ret == 0) {
		ret = sensor_read(SENSOR_ID_REG, &sensor_id, 1U);
	}
	if (ret == 0 && sensor_id == SENSOR_ID_PROFILE_6E) {
		ret = sensor_initialize_6e();
	}
	if (ret == 0 && sensor_id != SENSOR_ID_PROFILE_6E) {
		ret = -ENOTSUP;
	}
	if (ret == 0) {
		ret = sensor_set_dpi(active_dpi);
	}
	sensor_ok = ret == 0;
	if (sensor_ok) {
		spi_failures = 0U;
	} else {
		next_sensor_recovery_ms = k_uptime_get_32() + 1000U;
	}
	return ret;
}

static int sensor_set_dpi(uint16_t dpi)
{
	uint16_t encoded;
	int ret;

	if (dpi < G6_DPI_MIN || dpi > G6_DPI_MAX) {
		return -EINVAL;
	}
	encoded = dpi - 1U;

	ret = sensor_write(0x48U, (uint8_t)encoded);
	if (ret == 0) {
		ret = sensor_write(0x49U, (uint8_t)(encoded >> 8));
	}
	if (ret == 0) {
		ret = sensor_write(0x4aU, (uint8_t)encoded);
	}
	if (ret == 0) {
		ret = sensor_write(0x4bU, (uint8_t)(encoded >> 8));
	}
	if (ret == 0) {
		ret = sensor_write(0x47U, 0x01U);
	}
	return ret;
}

static int buttons_initialize(void)
{
	int ret;

	for (size_t i = 0; i < ARRAY_SIZE(button_pins); i++) {
		ret = gpio_pin_configure(gpio1, button_pins[i],
					 GPIO_INPUT | GPIO_PULL_UP);
		if (ret != 0) {
			return ret;
		}
	}
	ret = gpio_pin_configure(gpio0, 0U, GPIO_INPUT);
	if (ret == 0) {
		ret = gpio_pin_configure(gpio0, 1U, GPIO_INPUT);
	}
	if (ret != 0) {
		return ret;
	}

	last_wheel_state = ((uint8_t)gpio_pin_get_raw(gpio0, 1U) << 1) |
			   (uint8_t)gpio_pin_get_raw(gpio0, 0U);
	return 0;
}

static int buttons_read(uint8_t *buttons)
{
	uint8_t value = 0U;
	int pin_value;

	for (size_t i = 0; i < ARRAY_SIZE(button_pins); i++) {
		pin_value = gpio_pin_get_raw(gpio1, button_pins[i]);
		if (pin_value < 0) {
			return pin_value;
		}
		if (pin_value == 0) {
			value |= BIT(i);
		}
	}
	*buttons = value;
	return 0;
}

static int wheel_read(int8_t *wheel)
{
	int a = gpio_pin_get_raw(gpio0, 1U);
	int b = gpio_pin_get_raw(gpio0, 0U);
	uint8_t state;
	int8_t delta;

	if (a < 0 || b < 0) {
		return -EIO;
	}
	state = ((uint8_t)a << 1) | (uint8_t)b;
	delta = wheel_transition[(last_wheel_state << 2) | state];
	last_wheel_state = state;
	wheel_accumulator += delta;

	*wheel = 0;
	if (wheel_accumulator >= 4) {
		*wheel = 1;
		wheel_accumulator = 0;
	} else if (wheel_accumulator <= -4) {
		*wheel = -1;
		wheel_accumulator = 0;
	}
	return 0;
}

int g6_hw_init(void)
{
	int ret;

	if (!device_is_ready(gpio0) || !device_is_ready(gpio1) ||
	    !device_is_ready(gpio2) || !device_is_ready(sensor_spi)) {
		return -ENODEV;
	}

	ret = gpio_pin_configure(gpio2, 5U, GPIO_OUTPUT_HIGH);
	if (ret == 0) {
		ret = gpio_pin_configure(gpio2, 3U, GPIO_OUTPUT_HIGH);
	}
	if (ret != 0) {
		return ret;
	}

	ret = buttons_initialize();
	buttons_ok = ret == 0;
	if (ret != 0) {
		return ret;
	}

	(void)sensor_try_start();

	/* USB and optical buttons stay available if the sensor fails to start. */
	return 0;
}

int g6_hw_apply_config(const struct g6_config *cfg)
{
	if (!g6_config_valid(cfg)) {
		return -EINVAL;
	}
	if (!sensor_ok) {
		return -ENODEV;
	}

	/*
	 * The 0x6e sensor is capable of at least the requested 20 kFPS. The
	 * production driver exposes no literal frame-rate register; sensor_fps
	 * therefore selects a performance policy while DPI is applied here.
	 */
	active_dpi = cfg->dpi;
	return sensor_set_dpi(active_dpi);
}

int g6_hw_poll(struct g6_input_sample *sample)
{
	uint8_t motion[6];
	uint8_t buttons;
	int8_t wheel;
	int ret;

	if (sample == NULL) {
		return -EINVAL;
	}
	memset(sample, 0, sizeof(*sample));

	ret = buttons_read(&buttons);
	if (ret != 0) {
		buttons_ok = false;
		return ret;
	}
	ret = wheel_read(&wheel);
	if (ret != 0) {
		buttons_ok = false;
		return ret;
	}
	buttons_ok = true;

	if (!sensor_ok &&
	    (int32_t)(k_uptime_get_32() - next_sensor_recovery_ms) >= 0) {
		(void)sensor_try_start();
	}

	if (sensor_ok) {
		ret = sensor_read(SENSOR_MOTION_REG, motion, sizeof(motion));
		if (ret != 0) {
			sensor_ok = spi_failures < 8U;
			if (!sensor_ok) {
				next_sensor_recovery_ms = k_uptime_get_32() + 1000U;
			}
		} else {
			spi_failures = 0U;
			if ((int8_t)motion[0] < 0) {
				sample->dx = (int16_t)sys_get_le16(&motion[2]);
				sample->dy = -(int16_t)sys_get_le16(&motion[4]);
			}
		}
	}

	sample->raw_buttons = buttons;
	sample->wheel = wheel;
	sample->changed = buttons != last_buttons || wheel != 0 ||
			  sample->dx != 0 || sample->dy != 0;
	last_buttons = buttons;
	return 0;
}

bool g6_hw_sensor_ready(void)
{
	return sensor_ok;
}

bool g6_hw_buttons_ready(void)
{
	return buttons_ok;
}
```

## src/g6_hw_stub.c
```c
#include "g6_hw.h"

#include <errno.h>
#include <string.h>

/*
 * Safety stub: the G6 production GPIO/SPI map is not yet verified.
 * It deliberately drives no pins and reports no motion or button events.
 */

int g6_hw_init(void)
{
	return 0;
}

int g6_hw_apply_config(const struct g6_config *cfg)
{
	return g6_config_valid(cfg) ? 0 : -EINVAL;
}

int g6_hw_poll(struct g6_input_sample *sample)
{
	if (sample == NULL) {
		return -EINVAL;
	}

	memset(sample, 0, sizeof(*sample));
	return 0;
}

bool g6_hw_sensor_ready(void)
{
	return false;
}

bool g6_hw_buttons_ready(void)
{
	return false;
}
```

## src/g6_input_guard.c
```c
#include "g6_input_guard.h"

#include <stddef.h>

#define G6_CHORD_MASK (G6_RAW_BUTTON_MIDDLE | G6_RAW_BUTTON_BACK | \
		       G6_RAW_BUTTON_FORWARD)
#define G6_CHORD_WINDOW_MS 25U

static bool deadline_elapsed(uint32_t now_ms, uint32_t deadline_ms)
{
	return (int32_t)(now_ms - deadline_ms) >= 0;
}

void g6_input_guard_reset(struct g6_input_guard *guard)
{
	if (guard == NULL) {
		return;
	}
	guard->reported_buttons = 0U;
	guard->chord_deadline_ms = 0U;
	guard->chord_window_active = false;
	guard->combo_active = false;
}

bool g6_input_guard_process(struct g6_input_guard *guard, uint32_t now_ms,
			    uint8_t raw_buttons, uint8_t *filtered_buttons,
			    enum g6_control_event *event)
{
	uint8_t output;
	uint8_t chord;
	bool changed;

	if (guard == NULL || filtered_buttons == NULL || event == NULL) {
		return false;
	}

	*event = G6_CONTROL_NONE;
	chord = raw_buttons & G6_CHORD_MASK;

	if (guard->combo_active) {
		/* Never publish a member of a consumed chord. */
		output = raw_buttons & (uint8_t)~G6_CHORD_MASK;
		if (chord == 0U) {
			guard->combo_active = false;
		}
	} else if ((chord & G6_RAW_BUTTON_MIDDLE) != 0U &&
		   (chord & (G6_RAW_BUTTON_BACK | G6_RAW_BUTTON_FORWARD)) != 0U) {
		/* Back takes precedence if all three controls are held. */
		*event = (chord & G6_RAW_BUTTON_BACK) != 0U ?
			G6_CONTROL_CYCLE_POLLING : G6_CONTROL_CYCLE_DPI;
		guard->combo_active = true;
		guard->chord_window_active = false;
		output = raw_buttons & (uint8_t)~G6_CHORD_MASK;
	} else if (!guard->chord_window_active &&
		   ((raw_buttons ^ guard->reported_buttons) & G6_CHORD_MASK) != 0U) {
		/* Hold chord members long enough to recognise a human shortcut. */
		guard->chord_window_active = true;
		guard->chord_deadline_ms = now_ms + G6_CHORD_WINDOW_MS;
		output = (raw_buttons & (uint8_t)~G6_CHORD_MASK) |
			 (guard->reported_buttons & G6_CHORD_MASK);
	} else if (guard->chord_window_active &&
		   !deadline_elapsed(now_ms, guard->chord_deadline_ms)) {
		output = (raw_buttons & (uint8_t)~G6_CHORD_MASK) |
			 (guard->reported_buttons & G6_CHORD_MASK);
	} else {
		guard->chord_window_active = false;
		output = raw_buttons;
	}

	changed = output != guard->reported_buttons;
	guard->reported_buttons = output;
	*filtered_buttons = output;
	return changed;
}
```

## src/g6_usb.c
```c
#include "g6_usb.h"

#include <zephyr/device.h>
#include <zephyr/sys/util.h>
#include <zephyr/usb/bos.h>

#define G6_USB_VID 0x3434
#define G6_USB_PID 0xD687

USBD_DEVICE_DEFINE(g6_usbd,
		   DEVICE_DT_GET(DT_NODELABEL(zephyr_udc0)),
		   G6_USB_VID, G6_USB_PID);

USBD_DESC_LANG_DEFINE(g6_lang);
USBD_DESC_MANUFACTURER_DEFINE(g6_mfr, "G6 DIY Lab");
USBD_DESC_PRODUCT_DEFINE(g6_product, "G6 HE DIY DVT Fix v0.2");
USBD_DESC_SERIAL_NUMBER_DEFINE(g6_serial);

USBD_DESC_CONFIG_DEFINE(g6_fs_desc, "G6 HE FS");
USBD_DESC_CONFIG_DEFINE(g6_hs_desc, "G6 HE HS");

USBD_CONFIGURATION_DEFINE(g6_fs_config, USB_SCD_REMOTE_WAKEUP, 250U,
			  &g6_fs_desc);
USBD_CONFIGURATION_DEFINE(g6_hs_config, USB_SCD_REMOTE_WAKEUP, 250U,
			  &g6_hs_desc);

static const char *const class_blocklist[] = {
	"dfu_dfu",
	NULL,
};

static int add_descriptors(void)
{
	int ret;

	ret = usbd_add_descriptor(&g6_usbd, &g6_lang);
	if (ret != 0) {
		return ret;
	}
	ret = usbd_add_descriptor(&g6_usbd, &g6_mfr);
	if (ret != 0) {
		return ret;
	}
	ret = usbd_add_descriptor(&g6_usbd, &g6_product);
	if (ret != 0) {
		return ret;
	}
	return usbd_add_descriptor(&g6_usbd, &g6_serial);
}

static int add_configuration(enum usbd_speed speed,
			     struct usbd_config_node *config)
{
	int ret = usbd_add_configuration(&g6_usbd, speed, config);

	if (ret != 0) {
		return ret;
	}
	ret = usbd_register_all_classes(&g6_usbd, speed, 1,
					class_blocklist);
	if (ret != 0) {
		return ret;
	}
	usbd_device_set_code_triple(&g6_usbd, speed, 0, 0, 0);
	return 0;
}

struct usbd_context *g6_usb_init(void)
{
	int ret = add_descriptors();

	if (ret != 0) {
		return NULL;
	}

	if (USBD_SUPPORTS_HIGH_SPEED &&
	    usbd_caps_speed(&g6_usbd) == USBD_SPEED_HS) {
		ret = add_configuration(USBD_SPEED_HS, &g6_hs_config);
		if (ret != 0) {
			return NULL;
		}
	}

	ret = add_configuration(USBD_SPEED_FS, &g6_fs_config);
	if (ret != 0) {
		return NULL;
	}

	usbd_self_powered(&g6_usbd, false);
	ret = usbd_init(&g6_usbd);
	return ret == 0 ? &g6_usbd : NULL;
}
```
